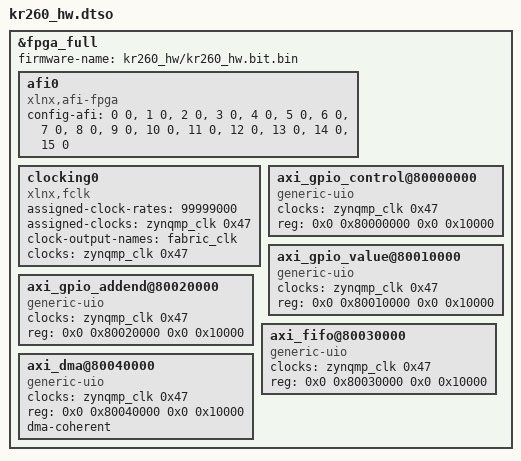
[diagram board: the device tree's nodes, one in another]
/dts-v1/;
/plugin/;

&fpga_full {
	#address-cells = <2>;
	#size-cells = <2>;
	firmware-name = "kr260_hw/kr260_hw.bit.bin";

	afi0 {
		compatible = "xlnx,afi-fpga";
		config-afi = <0 0>, <1 0>, <2 0>, <3 0>,
		             <4 0>, <5 0>, <6 0>, <7 0>,
		             <8 0>, <9 0>, <10 0>, <11 0>,
		             <12 0>, <13 0>, <14 0>, <15 0>;
	};

	clocking0 {
		#clock-cells = <0>;
		assigned-clock-rates = <99999000>;
		assigned-clocks = <&zynqmp_clk 0x47>;
		clock-output-names = "fabric_clk";
		clocks = <&zynqmp_clk 0x47>;
		compatible = "xlnx,fclk";
	};

	/* IPs moved into HPM0_LPD's 0x8000_0000+ aperture (Exp2: control plane
	 * via M_AXI_HPM0_LPD instead of M_AXI_HPM0_FPD).
	 * Old addresses were 0xA000_0000+, unreachable through the LPD master. */

	/* axi_gpio_control — single-channel, 2-bit opcode driving my_state.control. */
	axi_gpio_control@80000000 {
		clocks = <&zynqmp_clk 0x47>;
		compatible = "generic-uio";
		reg = <0x0 0x80000000 0x0 0x10000>;
	};

	/* axi_gpio_value — reads back the 64-bit accumulator (ch1=lo, ch2=hi). */
	axi_gpio_value@80010000 {
		clocks = <&zynqmp_clk 0x47>;
		compatible = "generic-uio";
		reg = <0x0 0x80010000 0x0 0x10000>;
	};

	/* axi_gpio_addend — 32-bit, drives my_state.value. */
	axi_gpio_addend@80020000 {
		clocks = <&zynqmp_clk 0x47>;
		compatible = "generic-uio";
		reg = <0x0 0x80020000 0x0 0x10000>;
	};

	/* axi_fifo_0 — AXI4-Lite simple FIFO with internal echo. */
	axi_fifo@80030000 {
		clocks = <&zynqmp_clk 0x47>;
		compatible = "generic-uio";
		reg = <0x0 0x80030000 0x0 0x10000>;
	};

	/* axi_dma_0 — AXI DMA, no SG, 64-bit MM2S+S2MM. MM2S→axis_data_fifo→S2MM
	 * loopback in PL. dma-coherent + PSU__AFI0_COHERENCY=1 → HPC0 snoop. */
	axi_dma@80040000 {
		clocks = <&zynqmp_clk 0x47>;
		compatible = "generic-uio";
		reg = <0x0 0x80040000 0x0 0x10000>;
		dma-coherent;
	};
};
